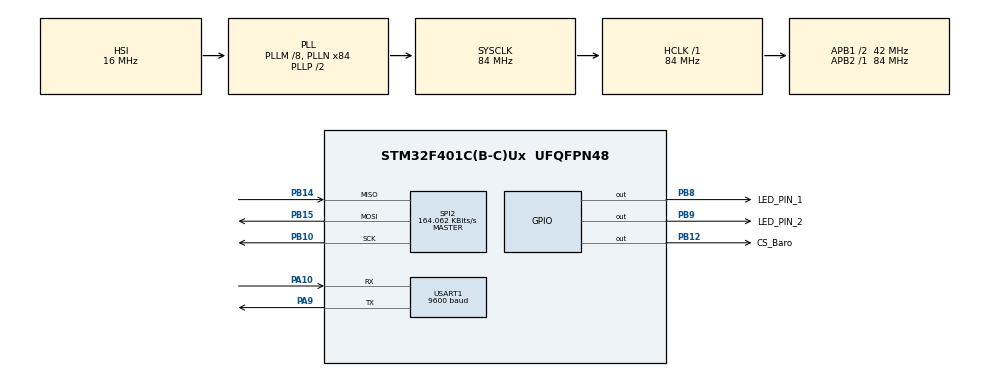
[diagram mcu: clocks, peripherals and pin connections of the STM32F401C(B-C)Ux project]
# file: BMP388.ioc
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Mcu.Family=STM32F4
Mcu.Name=STM32F401C(B-C)Ux
Mcu.Package=UFQFPN48
NVIC.PriorityGroup=NVIC_PRIORITYGROUP_4
PA10.Mode=Asynchronous
PA10.Signal=USART1_RX
PA9.Mode=Asynchronous
PA9.Signal=USART1_TX
PB10.Mode=Full_Duplex_Master
PB10.Signal=SPI2_SCK
PB12.GPIO_Label=CS_Baro
PB12.Signal=GPIO_Output
PB14.Mode=Full_Duplex_Master
PB14.Signal=SPI2_MISO
PB15.Mode=Full_Duplex_Master
PB15.Signal=SPI2_MOSI
PB8.GPIO_Label=LED_PIN_1
PB8.Signal=GPIO_Output
PB9.GPIO_Label=LED_PIN_2
PB9.PinState=GPIO_PIN_SET
PB9.Signal=GPIO_Output
ProjectManager.HeapSize=0x200
ProjectManager.StackSize=0x400
ProjectManager.TargetToolchain=STM32CubeIDE
RCC.48MHZClocksFreq_Value=42000000
RCC.AHBFreq_Value=84000000
RCC.APB1CLKDivider=RCC_HCLK_DIV2
RCC.APB1Freq_Value=42000000
RCC.APB1TimFreq_Value=84000000
RCC.APB2Freq_Value=84000000
RCC.APB2TimFreq_Value=84000000
RCC.CortexFreq_Value=84000000
RCC.HCLKFreq_Value=84000000
RCC.HSE_VALUE=25000000
RCC.HSI_VALUE=16000000
RCC.LSE_VALUE=32768
RCC.PLLM=8
RCC.PLLN=84
RCC.SYSCLKFreq_VALUE=84000000
RCC.SYSCLKSource=RCC_SYSCLKSOURCE_PLLCLK
RCC.VCOOutputFreq_Value=168000000
SPI2.BaudRatePrescaler=SPI_BAUDRATEPRESCALER_256
SPI2.CalculateBaudRate=164.062 KBits/s
SPI2.Direction=SPI_DIRECTION_2LINES
SPI2.Mode=SPI_MODE_MASTER
SPI2.VirtualType=VM_MASTER
USART1.BaudRate=9600
USART1.VirtualMode=VM_ASYNC
board=custom

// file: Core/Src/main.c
/* USER CODE BEGIN Header */
/**
  ******************************************************************************
  * @file           : main.c
  * @brief          : Main program body
  ******************************************************************************
  * @attention
  *
  * Copyright (c) 2026 STMicroelectronics.
  * All rights reserved.
  *
  * This software is licensed under terms that can be found in the LICENSE file
  * in the root directory of this software component.
  * If no LICENSE file comes with this software, it is provided AS-IS.
  *
  ******************************************************************************
  */
/* USER CODE END Header */
#include "main.h"

/* USER CODE BEGIN Includes */
#include "serial_print.h"
#include "bmp388.h"
/* USER CODE END Includes */

SPI_HandleTypeDef hspi2;

UART_HandleTypeDef huart1;

void SystemClock_Config(void);
static void MX_GPIO_Init(void);
static void MX_SPI2_Init(void);
static void MX_USART1_UART_Init(void);

int main(void)
{

  /* MCU Configuration--------------------------------------------------------*/

  /* Reset of all peripherals, Initializes the Flash interface and the Systick. */
  HAL_Init();

  /* Configure the system clock */
  SystemClock_Config();

  /* Initialize all configured peripherals */
  MX_GPIO_Init();
  MX_SPI2_Init();
  MX_USART1_UART_Init();
  /* USER CODE BEGIN 2 */
  Serial_PrintString(&huart1, "ready  ");
    while(1){
    //HAL_Delay(10); // Ждем запуска датчика
      Serial_Printf(&huart1, "ANS: %u\r\n", BMP388_ReadReg(0x0f));
    }
  if (BMP388_Init(&hspi2) != BMP388_OK) {
	  // Ошибка инициализации
	  Serial_PrintString(&huart1, "ERROR\r\n");
  }
  /* USER CODE END 2 */

  /* Infinite loop */
  while (1)
  {

  }
}

void SystemClock_Config(void)
{
  RCC_OscInitTypeDef RCC_OscInitStruct = {0};
  RCC_ClkInitTypeDef RCC_ClkInitStruct = {0};

  /** Configure the main internal regulator output voltage
  */
  __HAL_RCC_PWR_CLK_ENABLE();
  __HAL_PWR_VOLTAGESCALING_CONFIG(PWR_REGULATOR_VOLTAGE_SCALE2);

  /** Initializes the RCC Oscillators according to the specified parameters
  * in the RCC_OscInitTypeDef structure.
  */
  RCC_OscInitStruct.OscillatorType = RCC_OSCILLATORTYPE_HSI;
  RCC_OscInitStruct.HSIState = RCC_HSI_ON;
  RCC_OscInitStruct.HSICalibrationValue = RCC_HSICALIBRATION_DEFAULT;
  RCC_OscInitStruct.PLL.PLLState = RCC_PLL_ON;
  RCC_OscInitStruct.PLL.PLLSource = RCC_PLLSOURCE_HSI;
  RCC_OscInitStruct.PLL.PLLM = 8;
  RCC_OscInitStruct.PLL.PLLN = 84;
  RCC_OscInitStruct.PLL.PLLP = RCC_PLLP_DIV2;
  RCC_OscInitStruct.PLL.PLLQ = 4;
  if (HAL_RCC_OscConfig(&RCC_OscInitStruct) != HAL_OK)
  {
    Error_Handler();
  }

  /** Initializes the CPU, AHB and APB buses clocks
  */
  RCC_ClkInitStruct.ClockType = RCC_CLOCKTYPE_HCLK|RCC_CLOCKTYPE_SYSCLK
                              |RCC_CLOCKTYPE_PCLK1|RCC_CLOCKTYPE_PCLK2;
  RCC_ClkInitStruct.SYSCLKSource = RCC_SYSCLKSOURCE_PLLCLK;
  RCC_ClkInitStruct.AHBCLKDivider = RCC_SYSCLK_DIV1;
  RCC_ClkInitStruct.APB1CLKDivider = RCC_HCLK_DIV2;
  RCC_ClkInitStruct.APB2CLKDivider = RCC_HCLK_DIV1;

  if (HAL_RCC_ClockConfig(&RCC_ClkInitStruct, FLASH_LATENCY_2) != HAL_OK)
  {
    Error_Handler();
  }
}

static void MX_SPI2_Init(void)
{

  /* SPI2 parameter configuration*/
  hspi2.Instance = SPI2;
  hspi2.Init.Mode = SPI_MODE_MASTER;
  hspi2.Init.Direction = SPI_DIRECTION_2LINES;
  hspi2.Init.DataSize = SPI_DATASIZE_8BIT;
  hspi2.Init.CLKPolarity = SPI_POLARITY_LOW;
  hspi2.Init.CLKPhase = SPI_PHASE_1EDGE;
  hspi2.Init.NSS = SPI_NSS_SOFT;
  hspi2.Init.BaudRatePrescaler = SPI_BAUDRATEPRESCALER_256;
  hspi2.Init.FirstBit = SPI_FIRSTBIT_MSB;
  hspi2.Init.TIMode = SPI_TIMODE_DISABLE;
  hspi2.Init.CRCCalculation = SPI_CRCCALCULATION_DISABLE;
  hspi2.Init.CRCPolynomial = 10;
  if (HAL_SPI_Init(&hspi2) != HAL_OK)
  {
    Error_Handler();
  }

}

static void MX_USART1_UART_Init(void)
{

  huart1.Instance = USART1;
  huart1.Init.BaudRate = 9600;
  huart1.Init.WordLength = UART_WORDLENGTH_8B;
  huart1.Init.StopBits = UART_STOPBITS_1;
  huart1.Init.Parity = UART_PARITY_NONE;
  huart1.Init.Mode = UART_MODE_TX_RX;
  huart1.Init.HwFlowCtl = UART_HWCONTROL_NONE;
  huart1.Init.OverSampling = UART_OVERSAMPLING_16;
  if (HAL_UART_Init(&huart1) != HAL_OK)
  {
    Error_Handler();
  }

}

static void MX_GPIO_Init(void)
{
  GPIO_InitTypeDef GPIO_InitStruct = {0};

  /* GPIO Ports Clock Enable */
  __HAL_RCC_GPIOB_CLK_ENABLE();
  __HAL_RCC_GPIOA_CLK_ENABLE();

  /*Configure GPIO pin Output Level */
  HAL_GPIO_WritePin(GPIOB, CS_Baro_Pin|LED_PIN_1_Pin, GPIO_PIN_RESET);

  /*Configure GPIO pin Output Level */
  HAL_GPIO_WritePin(LED_PIN_2_GPIO_Port, LED_PIN_2_Pin, GPIO_PIN_SET);

  /*Configure GPIO pins : CS_Baro_Pin LED_PIN_1_Pin LED_PIN_2_Pin */
  GPIO_InitStruct.Pin = CS_Baro_Pin|LED_PIN_1_Pin|LED_PIN_2_Pin;
  GPIO_InitStruct.Mode = GPIO_MODE_OUTPUT_PP;
  GPIO_InitStruct.Pull = GPIO_NOPULL;
  GPIO_InitStruct.Speed = GPIO_SPEED_FREQ_LOW;
  HAL_GPIO_Init(GPIOB, &GPIO_InitStruct);

}

void Error_Handler(void)
{
  __disable_irq();
  while (1)
  {
  }
}
